# haltium_secure register map
Vendor: Nordic Semiconductor; Series: nRFHaltium; File version: 1
CPU: CM33 r0p4, little endian, MPU, FPU, 3 interrupt priority bits, 480 interrupts
Registers are 32-bit, read-write, reset 0x0 unless marked. A register's access mark holds for its fields unless they carry their own. Offsets are from the block's base; [hi:lo] are bit positions; lines under a group give offsets from that group; {n}, {i} and the like mark numbered series; 'fields as' and 'values as' point back to an identical list.

## MEMCONF200_S — Memory configuration 0
Base 0xBF008000
Same registers: MEMCONF_NS 0x41012000, MEMCONF_S 0x51012000
{0x500+0x10*i} POWER[{i}] (i=0..3) group — Unspecified
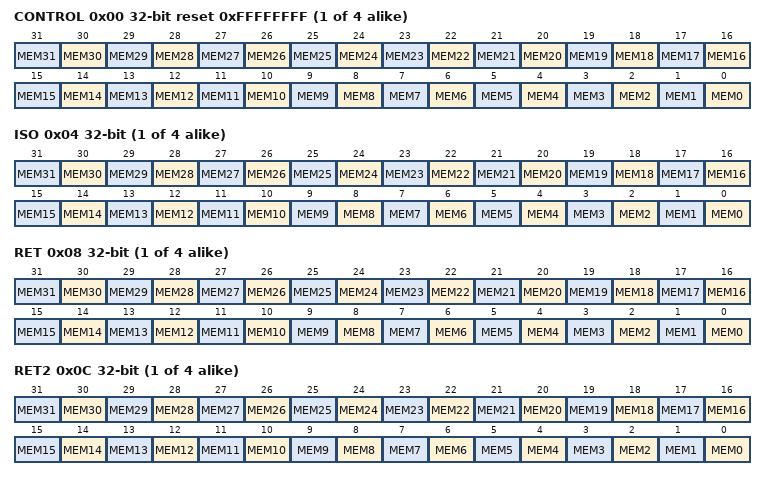
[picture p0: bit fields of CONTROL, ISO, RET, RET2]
  0x00 CONTROL reset 0xFFFFFFFF — Description cluster: RAM/ROM[n] power control register.
    [all] fields
      0=Off (Power down); 1=On (Power up)
    [n] MEM{n} (n=0..31) — Keep the RAM/ROM block MEM[{n}] on or off when in System ON mode.
  0x04 ISO — Description cluster: RAM/ROM [n] power isolation control register.
    [all] fields
      0=Off (Isolation off); 1=On (Isolation on)
    [n] MEM{n} (n=0..31) — Turn on/off the power isolation for RAM/ROM block MEM[{n}].
  0x08 RET — Description cluster: RAM retention for RAM/ROM [n].
    [all] fields
      0=Off (Retention off); 1=On (Retention on)
    [n] MEM{n} (n=0..31) — Keep the RAM block MEM[{n}] retained when in System OFF mode.
  0x0C RET2 — Description cluster: RAM retention for the second bank in the RAM block
    [all] fields
      0=Off (Retention off); 1=On (Retention on)
    [n] MEM{n} (n=0..31) — Keep the second bank in RAM block MEM[{n}] retained when in System OFF mode.
{0x600+0x18*i} REPAIR[{i}] (i=0..31) group — Unspecified
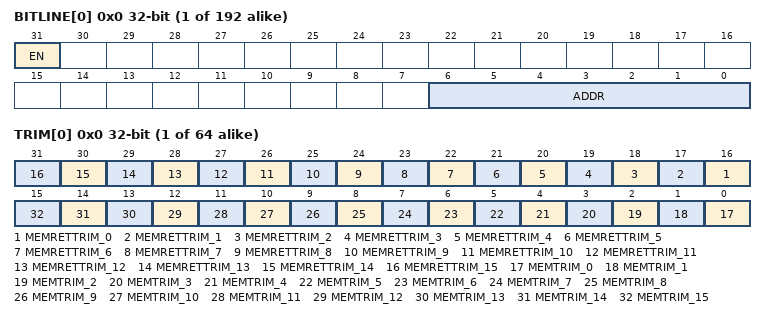
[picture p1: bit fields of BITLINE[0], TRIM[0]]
  {0x0+4j} BITLINE[{j}] (j=0..5) — Description collection: RAM repair bitline configuration RAM/ROM blocks.
    [31] EN — Enable bitline repair
      0=Disabled (Repair disabled.); 1=Enabled (Repair enabled.)
    [6:0] ADDR — Repair address of the bitline
0x900 BLOCKTYPE group — Unspecified
  {0x0+4j} TRIM[{j}] (j=0..63) — Description collection: Trim configuration for the RAM/ROM block types.
    [n+16] MEMRETTRIM_{n} (n=0..15) — Trimming for retention mode for decreased leakage. Must be kept active in RAM retention mode.
    [n] MEMTRIM_{n} (n=0..15) — Read/write margin trim.

## GLOBAL_TSGEN_NS — GENERIC 0
Base 0xBF041000
Same registers: GLOBAL_CAN_NS 0x4F8D5000, GLOBAL_CAN_S 0x5F8D5000, GLOBAL_ETB_NS 0xBF044000, GLOBAL_ETR_NS 0xBF045000
0x00 TASKS_GENERICTASK wo — Generic event
  [0] TASKS_GENERICTASK
    1=Trigger task
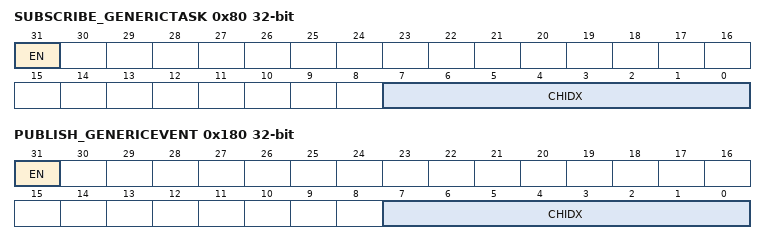
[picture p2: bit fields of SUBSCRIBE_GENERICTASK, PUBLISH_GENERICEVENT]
0x80 SUBSCRIBE_GENERICTASK — Subscribe configuration for task GENERICTASK
  [31] EN
    0=Disabled (Disable subscription); 1=Enabled (Enable subscription)
  [7:0] CHIDX — DPPI channel that task GENERICTASK will subscribe to
0x100 EVENTS_GENERICEVENT — Generic event
  [0] EVENTS_GENERICEVENT
    0=NotGenerated (Event not generated); 1=Generated (Event generated)
0x180 PUBLISH_GENERICEVENT — Publish configuration for event GENERICEVENT
  [31] EN
    0=Disabled (Disable publishing); 1=Enabled (Enable publishing)
  [7:0] CHIDX — DPPI channel that event GENERICEVENT will publish to
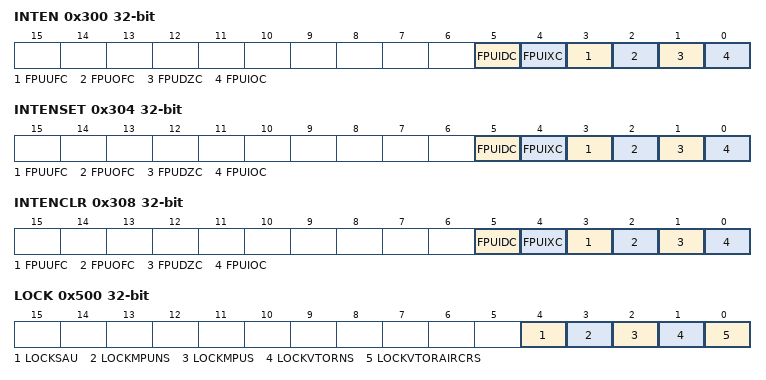
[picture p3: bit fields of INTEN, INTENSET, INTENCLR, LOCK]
0x300 INTEN — Enable or disable interrupt
  [0] GENERICEVENT — Enable or disable interrupt for event GENERICEVENT
    0=Disabled; 1=Enabled
0x304 INTENSET — Enable interrupt
  [0] GENERICEVENT — Write '1' to enable interrupt for event GENERICEVENT
    on read: 0=Disabled (Read: Disabled); 1=Enabled (Read: Enabled) | on write: 1=Set (Enable)
0x308 INTENCLR — Disable interrupt
  [0] GENERICEVENT — Write '1' to disable interrupt for event GENERICEVENT
    on read: 0=Disabled (Read: Disabled); 1=Enabled (Read: Enabled) | on write: 1=Clear (Disable)

## CPUC_S — CM33 SubSystem
Base 0xE0080000
0x100 EVENTS_FPUIOC — An invalid operation exception has occurred in the FPU.
  [0] EVENTS_FPUIOC
    0=NotGenerated (Event not generated); 1=Generated (Event generated)
0x104 EVENTS_FPUDZC — A floating-point divide-by-zero exception has occurred in the FPU.
  [0] EVENTS_FPUDZC
    values as EVENTS_FPUIOC.EVENTS_FPUIOC
0x108 EVENTS_FPUOFC — A floating-point overflow exception has occurred in the FPU.
  [0] EVENTS_FPUOFC
    values as EVENTS_FPUIOC.EVENTS_FPUIOC
0x10C EVENTS_FPUUFC — A floating-point underflow exception has occurred in the FPU.
  [0] EVENTS_FPUUFC
    values as EVENTS_FPUIOC.EVENTS_FPUIOC
0x110 EVENTS_FPUIXC — A floating-point inexact exception has occurred in the FPU.
  [0] EVENTS_FPUIXC
    values as EVENTS_FPUIOC.EVENTS_FPUIOC
0x114 EVENTS_FPUIDC — A floating-point input denormal exception has occurred in the FPU.
  [0] EVENTS_FPUIDC
    values as EVENTS_FPUIOC.EVENTS_FPUIOC
0x300 INTEN — Enable or disable interrupt
  [all] fields
    0=Disabled; 1=Enabled
  [5] FPUIDC — Enable or disable interrupt for event FPUIDC
  [4] FPUIXC — Enable or disable interrupt for event FPUIXC
  [3] FPUUFC — Enable or disable interrupt for event FPUUFC
  [2] FPUOFC — Enable or disable interrupt for event FPUOFC
  [1] FPUDZC — Enable or disable interrupt for event FPUDZC
  [0] FPUIOC — Enable or disable interrupt for event FPUIOC
0x304 INTENSET — Enable interrupt
  [all] fields
    on read: 0=Disabled (Read: Disabled); 1=Enabled (Read: Enabled) | on write: 1=Set (Enable)
  [5] FPUIDC — Write '1' to enable interrupt for event FPUIDC
  [4] FPUIXC — Write '1' to enable interrupt for event FPUIXC
  [3] FPUUFC — Write '1' to enable interrupt for event FPUUFC
  [2] FPUOFC — Write '1' to enable interrupt for event FPUOFC
  [1] FPUDZC — Write '1' to enable interrupt for event FPUDZC
  [0] FPUIOC — Write '1' to enable interrupt for event FPUIOC
0x308 INTENCLR — Disable interrupt
  [all] fields
    on read: 0=Disabled (Read: Disabled); 1=Enabled (Read: Enabled) | on write: 1=Clear (Disable)
  [5] FPUIDC — Write '1' to disable interrupt for event FPUIDC
  [4] FPUIXC — Write '1' to disable interrupt for event FPUIXC
  [3] FPUUFC — Write '1' to disable interrupt for event FPUUFC
  [2] FPUOFC — Write '1' to disable interrupt for event FPUOFC
  [1] FPUDZC — Write '1' to disable interrupt for event FPUDZC
  [0] FPUIOC — Write '1' to disable interrupt for event FPUIOC
0x500 LOCK — Register to lock the certain parts of the CPU from being modified.
  [4] LOCKSAU — Locks the Security Attribution Unit (SAU)
    0=NotLocked (SAU registers can be changed.); 1=Locked (Prevents changes to SAU registers.)
  [3] LOCKMPUNS — Locks the Memory Protection Unit (MPU) for non secure mode.
    0=NotLocked (MPU registers can be changed.); 1=Locked (Prevents changes to MPU registers.)
  [2] LOCKMPUS — Locks the Memory Protection Unit (MPU) for secure mode.
    values as LOCKMPUNS
  [1] LOCKVTORNS — Locks the Vector table Offset Register (VTOR) for non-secure mode.
    0=NotLocked (VTOR can be changed.); 1=Locked (Prevents changes to VTOR.)
  [0] LOCKVTORAIRCRS — Locks both the Vector table Offset Register (VTOR) and Application Interrupt and Reset Control Register (AIRCR) for secure mode.
    0=NotLocked (Both VTOR and AIRCR can be changed.); 1=Locked (Prevents changes to both VTOR and AIRCR.)
0x504 CPUID ro — The identifier for the CPU in this subsystem.
  [31:0] CPUID — The CPU identifier.
